# R7FA8M1AH register map
Vendor: Renesas; Series: RA8; File version: 1.2
CPU: CM85 r0p0, little endian, MPU, FPU, VTOR, 4 interrupt priority bits
Registers are 32-bit, read-write, reset 0x0 unless marked. A register's access mark holds for its fields unless they carry their own. Offsets are from the block's base; [hi:lo] are bit positions; <NAME> marks a mode.

## CPU_OCD — On-Chip Debug
Base 0x40011000
Same registers: CPU_OCD_NS 0x50011000
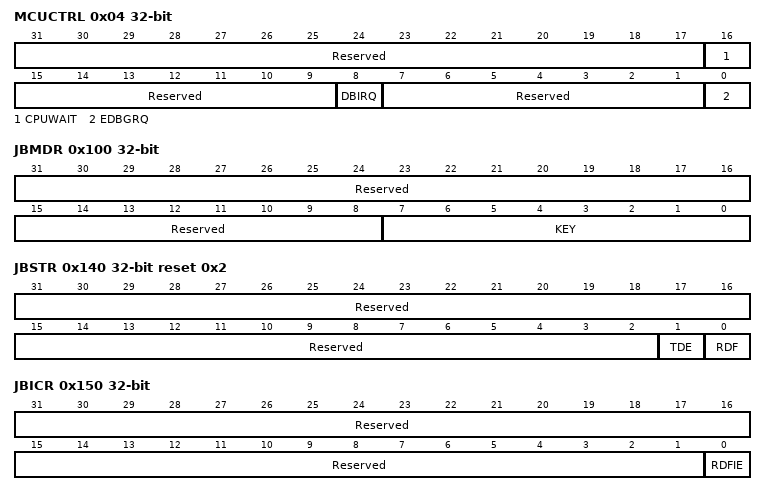
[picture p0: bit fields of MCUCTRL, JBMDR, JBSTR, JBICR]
0x04 MCUCTRL — MCU Control Register
  [31:17] Reserved — These bits are read as 000000000000000. The write value should be 000000000000000.
  [16] CPUWAIT — CPU WAIT SETTING
    0=Clear CPUWAIT to Low; 1=Set CPUWAIT to High
  [15:9] Reserved — These bits are read as 0000000. The write value should be 0000000.
  [8] DBIRQ — Writing 1 to the bit wakes up the CPU from Deep Sleep mode or the MCU from Software Standby Mode or Seep Software Standby mode
    0=Debug interrupt is not requested; 1=Debug interrupt requested
  [7:1] Reserved — These bits are read as 0000000. The write value should be 0000000.
  [0] EDBGRQ — External Debug Request. Writing 1 to the bit causes CPU Halt or Debug Monitor exception request.
    0=Not request Debug Event; 1=Request Debug Event
0x100 JBMDR — JTAG Boot Mode Entry Register
  [31:16] Reserved — These bits are read as 0000000000000000. The write value should be 0000000000000000.
  [15:8] Reserved — These bits are read as 00000000. The write value should be 00000000.
  [7:0] KEY — Mode entry key
0x120 JBRDR — JTAG Boot Receive Data Register
  [31:0] RDAT — Received data register
0x130 JBTDR — JTAG Boot Transmit Data Register
  [31:0] TDAT — Transmitted data register
0x140 JBSTR reset 0x2 — JTAG Boot Status register for External Host
  [31:16] Reserved — These bits are read as 0000000000000000. The write value should be 0000000000000000.
  [15:2] Reserved — These bits are read as 00000000000000. The write value should be 00000000000000.
  [1] TDE — Transmit data empty
    0=There is data transmission; 1=No data transmission
  [0] RDF — Receive buffer full
    0=No receiving data; 1=There is receiving data
0x150 JBICR — JTAG Boot Interrupt Control Register
  [31:16] Reserved — These bits are read as 0000000000000000. The write value should be 0000000000000000.
  [15:1] Reserved — These bits are read as 000000000000000. The write value should be 000000000000000.
  [0] RDFIE — Receive buffer full interrupt enabled
    0=Interrupt request disabled by RDF = 1; 1=Enable interrupt request by RDF = 1
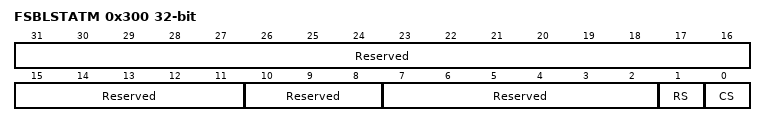
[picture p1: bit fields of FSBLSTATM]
0x300 FSBLSTATM ro — First Stage Boot Loader Status Monitor Register
  [31:16] Reserved — These bits are read as 0000000000000000.
  [15:11] Reserved — These bits are read as 00000.
  [10:8] Reserved — These bits are read as 000.
  [7:2] Reserved — These bits are read as 000000.
  [1] RS — FSBL result status.
    0=FSBL failed; 1=FSBL passed
  [0] CS — FSBL completion status.
    0=FSBL isn't complete; 1=FSBL is complete

## FCACHE — Flash Cache
Base 0x4001C100
Same registers: FCACHE_NS 0x5001C100
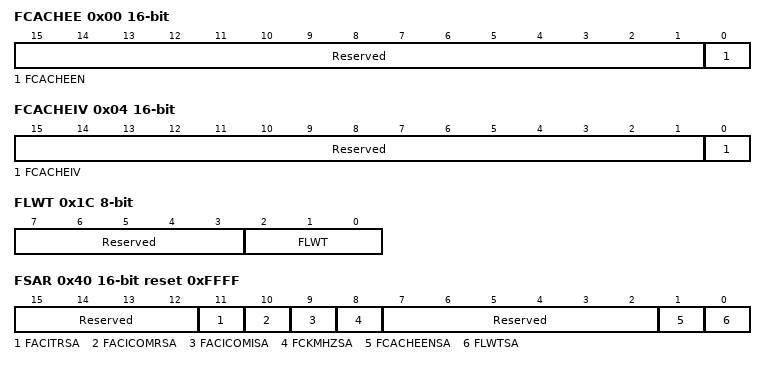
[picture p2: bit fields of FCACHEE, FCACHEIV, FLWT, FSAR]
0x00 FCACHEE 16-bit — Flash Cache Enable Register
  [15:1] Reserved — These bits are read as 000000000000000. The write value should be 000000000000000.
  [0] FCACHEEN — Flash Cache Enable
    0=FCACHE is disabled; 1=FCACHE is enabled
0x04 FCACHEIV 16-bit — Flash Cache Invalidate Register
  [15:1] Reserved — These bits are read as 000000000000000. The write value should be 000000000000000.
  [0] FCACHEIV write-1-sets read-modifies — Flash Cache Invalidate
    0=Read : Do not invalidate. Write: the setting is ignored.; 1=FCACHE is invalidated
0x1C FLWT 8-bit — Flash Wait Cycle Register
  [7:3] Reserved — These bits are read as 00000. The write value should be 00000.
  [2:0] FLWT — Flash Wait Cycle
    0=0 wait (ICLK <= 48MHz); 1=1 wait (48MHz < ICLK <= 96MHz); 2=2 waits (96MHz < ICLK <= 144MHz); 3=3 waits (144Hz < ICLK <= 192MHz); 4=4 waits (192Hz < ICLK <= 240MHz); other=others (Setting prohibited)
0x40 FSAR 16-bit reset 0xFFFF (reset mask 0x0) — Flash Security Attribution Register
  [15:12] Reserved — These bits are read as 1111. The write value should be 1111.
  [11] FACITRSA — FACI transfer Security Attribution
    0=Secure; 1=Non-Secure
  [10] FACICOMRSA — FACI command Registers Security Attribution
    0=Secure; 1=Non-Secure
  [9] FACICOMISA — FACI command Issuing Security Attribution
    0=Secure; 1=Non-Secure
  [8] FCKMHZSA — FCKMHZ Security Attribution
    0=Secure; 1=Non-Secure
  [7:2] Reserved — These bits are read as 111111. The write value should be 111111.
  [1] FCACHEENSA — FCHACHEEN Security Attribution
    0=Secure; 1=Non-Secure
  [0] FLWTSA — FLWT Security Attribution
    0=Secure; 1=Non-Secure
